# SC32F10T_10G register map
File version: 1.0
CPU: CM0+ r0p1, little endian, MPU, no FPU, 4 interrupt priority bits
Registers are 32-bit, read-write, reset 0x0 unless marked. A register's access mark holds for its fields unless they carry their own. Offsets are from the block's base; [hi:lo] are bit positions.

## INTF — 外部中断
Base 0x40011300
0x00 INTF_IE — INT中断下降沿使能寄存器
  [15:0] ENFx（x — INTx下降沿中断使能控制位（x=0~15）0：无效1：使能
0x20 INTR_IE — INT中断上升沿使能寄存器
  [15:0] ENRx（x — INTx上升沿中断使能控制位（x=0~15）0：无效1：使能
0x40 INT_SEL0 — 外部中断端口选择寄存器0
  [31:0] INTxSEL（x — 外部中断INTx端口选择位（x=0~7）0000：选择PAx端口0001：选择PBx端口0010：选择PCx端口其它：保留
0x60 INT_SEL1 — 外部中断端口选择寄存器1
  [31:0] INTxSEL（x — 外部中断INTx端口选择位（x=8~15）0000：选择PAx端口0001：选择PBx端口0010：选择PCx端口其它：保留
0x80 INTF_CON — 外部中断下降沿控制寄存器
  [15:0] FTx（x — INTx下降沿检测使能（x=0~15）0：无效1：使能
0xA0 INTR_CON — 外部中断上升沿控制寄存器
  [15:0] RTx（x — INTx上升沿检测使能（x=0~15）0：无效1：使能
0xC0 INTF_STS — 外部中断下降沿标志寄存器
  [15:0] FIFx（x — INTx端口下降沿捕获标志位（x=0~15）检测到下降沿，该位由硬件置1，通过软件写0清0。也可通过软件对该位写1触发下降沿捕获中断。
0xE0 INTR_STS — 外部中断上升沿标志寄存器
  [15:0] RIFx（x — INTx端口上升沿捕获标志位（x=0~15）检测到上升沿，该位由硬件置1，通过软件写0清0。也可通过软件对该位写1触发上升沿捕获中断。

## PA
Base 0x40011000
0x00 PA access not given — PA端口数据寄存器
0x20 PACON access not given — PA口输入/输出控制寄存器
0x40 PAPH access not given — PA口上拉电阻控制寄存器
0x60 PALEV access not given — IOH设置寄存器 IO驱动等级

## PB
Base 0x40011100
0x00 PB access not given — PB端口数据寄存器
0x20 PBCON access not given — PB口输入/输出控制寄存器
0x40 PBPH access not given — PB口上拉电阻控制寄存器
0x60 PBLEV access not given — IOH设置寄存器 IO驱动等级

## PC
Base 0x40011200
0x00 PC access not given — PC端口数据寄存器
0x20 PCCON access not given — PC口输入/输出控制寄存器
0x40 PCPH access not given — PC口上拉电阻控制寄存器
0x60 PCLEV access not given — IOH设置寄存器 IO驱动等级

## ADC
Base 0x40022110
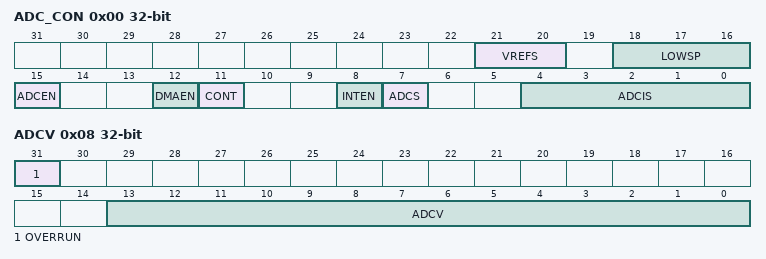
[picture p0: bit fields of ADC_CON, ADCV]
0x00 ADC_CON — ADC控制寄存器
  [21:20] VREFS — 参考电压选择控制位00：选择ADC的VREF为VDD； 01：选择ADC的VREF为内部准确的2.048V； 10：选择ADC的VREF为内部准确的1.024V； 11：选择ADC的VREF为内部准确的2.4V；
  [18:16] LOWSP — ADC 采样周期数选择控制位 100：采样时间为3个系统时钟，（约 100ns @ fPCLK2 = 32MHz） 101：采样时间约6个系统时钟，（约 200ns @ fPCLK2 = 32MHz） 110：采样时间约 16个系统时钟，（约 500ns @ fPCLK2 = 32MHz） 111：采样时间约 32个系统时钟，（约 1000ns @ fPCLK2 = 32MHz） 其它：保留 说明
  [15] ADCEN — ADC模块电源启动控制位 0：关闭ADC模块电源 1：开启ADC 模块电源
  [12] DMAEN — DMA请求使能控制位 该位用于使能 DMA 请求的生成。写1后可使用 DMA 控制器自动管理ADC转换的数据。 0：禁止 DMA请求 1：使能 DMA请求 注意：通过软件对此位执行写操作时，应确保当前未进行任何转换。
  [11] CONT — 单次/连续转换模式选择位该位由软件置 1 和清0。该位置 1 时，转换将持续进行，直到该位清0。 0：单次转换模式 1：连续转换模式
  [8] INTEN — 中断请求 CPU的使能控制位 0：禁止中断请求 1：使能中断请求
  [7] ADCS — ADC转换触发控制位该位是ADC转换的触发信号，由软件置 1 ，由硬件清0。对此位写 1 会触发一次 ADC 的转换。 注意：对ADCS置1之后，到中断标志ADCIF置起前不要对ADC_CON寄存器进行写操作。
  [4:0] ADCIS — ADC 输入通道选择位 00000：选择 AIN0 为 ADC 的输入 00001：选择AIN1 为 ADC 的输入 00111：选择 AIN7为 ADC 的输入 01000：选择 AIN8为 ADC 的输入 01001：选择AIN9 为 ADC 的输入 01010：选择AIN10 为 ADC 的输入 01011：选择AIN11 为 ADC 的输入 01100：选择AIN12 为 ADC 的输入
0x04 ADC_STS — ADC标志状态位寄存器
  [0] ADCIF — ADC中断请求标志位该位由硬件置1，通过软件写1清0。ADC转换完成后，该位由硬件置1，如果ADC_CON.INTEN=1，将产生中断。
0x08 ADCV access per field — ADC转换数值寄存器
  [31] OVERRUN ro — 溢出标志位（只读）当CPU或DMA无法及时处理ADC转换请求而发生溢出时，该位由硬件置1，读取ADCV后，该位自动清0。 注意：产生溢出时，上一次的ADC转换结果将被新的ADC转换结果覆盖。
  [13:0] ADCV rw — 14位的ADC转换结果
0x0C ADC_CFG — ADC端口设置寄存器
  [71] AINx（x — ADC端口设置寄存器0：未选定AINx，AINx所在管脚为GPIO，或其它复用功能1：选定AINx为ADC输入，并自动将AINx所在端口的上拉电阻移除

## CMP
Base 0x40022110
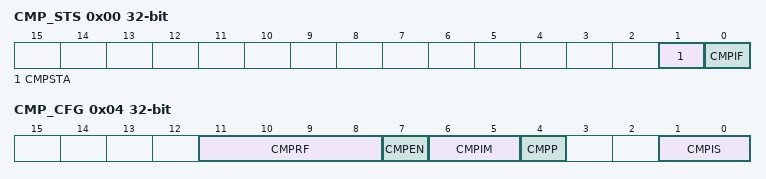
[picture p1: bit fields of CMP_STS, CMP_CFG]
0x00 CMP_STS — 模拟比较器状态寄存器
  [1] CMPSTA — 模拟比较器输出状态位0：比较器正端电压小于负端电压1：比较器正端电压大于负端电压
  [0] CMPIF — 模拟比较器中断标志位该位由硬件置1，通过软件写1清0。0：比较器中断未被触发；1：当比较器满足中断触发条件时，此位会被硬件置 1。如果此时 CMPIM[1:0]不为00, 比较器中断产生。
0x04 CMP_CFG — 模拟比较器配置寄存器
  [11:8] CMPRF — 模拟比较器负端比较电压选择位模拟比较器负端比较电压设置项如下：0000： CMPR；0001： 1/16VDD 0010： 2/16VDD 0011： 3/16VDD 0100： 4/16VDD 0101： 5/16VDD 0110： 6/16VDD 0111： 7/16VDD 1000： 8/16VDD 1001： 9/16VDD 1010： 10/16VDD 1011： 11/16VDD 11
  [7] CMPEN — 模拟比较器使能位0：关闭模拟比较器1：使能模拟比较器
  [6:5] CMPIM — 模拟比较器中断模式选择位00：不产生中断01：上升沿中断：IN+从小于 IN- 到大于 IN- 后会产生中断；10：下降沿中断：IN+从大于 IN- 到小于 IN- 后会产生中断；11：双沿中断：IN+从小于 IN- 到大于 IN- ，或IN+从大于 IN- 到小于 IN-后均会产生中断；
  [4] CMPP — 模拟比较器正端输入选择：0：模拟比较器正端的输入为CMP0~3之一为，由CMPIS[1:0]设定1：模拟比较器正端的输入为内部1.5V基准电压
  [1:0] CMPIS — 模拟比较器正端输入通道选择位CMPP为1时，该位无效：00：选用 CMP0 为模拟比较器正端的输入；01：选用 CMP1 为模拟比较器正端的输入；10：选用 CMP2 为模拟比较器正端的输入；11：选用 CMP3 为模拟比较器正端的输入；
